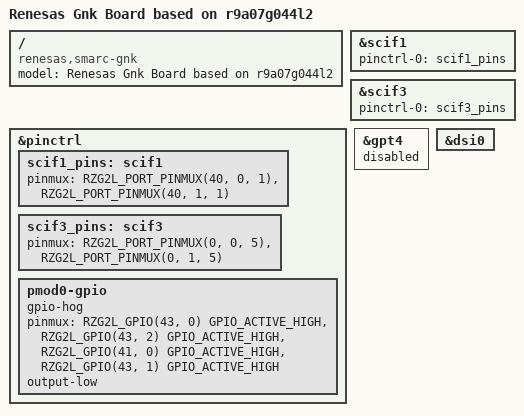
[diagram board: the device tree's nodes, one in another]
// SPDX-License-Identifier: (GPL-2.0-only OR BSD-2-Clause)
/*
 * Device Tree Source for the RZ/G2L SMARC PHOENIX board
 *
 * Copyright (C) 2022 Regulus Corp.
 */

/dts-v1/;
#include "r9a07g044l2.dtsi"
#include "rzg2l-smarc-som.dtsi"
#include "rzg2l-smarc-pinfunction.dtsi"
#include "rz-gnk-smarc-common.dtsi"


/ {
	model = "Renesas Gnk Board based on r9a07g044l2";
	compatible = "renesas,smarc-gnk", "renesas,r9a07g044l2", "renesas,r9a07g044";
};

&scif1 {
	pinctrl-0 = <&scif1_pins>;
	pinctrl-names = "default";
	status = "okay";
};

&scif3 {
	pinctrl-0 = <&scif3_pins>;
	pinctrl-names = "default";
	status = "okay";
};


&pinctrl {
	/delete-node/ can0-stb;
	/delete-node/ can1-stb;
	scif1_pins: scif1 {
		pinmux = <RZG2L_PORT_PINMUX(40, 0, 1)>,	/* TxD */
			 <RZG2L_PORT_PINMUX(40, 1, 1)>;	/* RxD */
	};

	scif3_pins: scif3 {
		pinmux = <RZG2L_PORT_PINMUX(0, 0, 5)>,	/* TxD */
			 <RZG2L_PORT_PINMUX(0, 1, 5)>;	/* RxD */
	};

	pmod0-gpio {
		gpio-hog;
		pinmux = <RZG2L_GPIO(43, 0) GPIO_ACTIVE_HIGH>,
			<RZG2L_GPIO(43, 2) GPIO_ACTIVE_HIGH>,
			<RZG2L_GPIO(41, 0) GPIO_ACTIVE_HIGH>,
			<RZG2L_GPIO(43, 1) GPIO_ACTIVE_HIGH>;
		output-low;
	};
};

&gpt4 {
	status = "disabled";
};

&dsi0 {
	status = "okay";
};
